# FM33A0XXER register map
File version: 1.0
CPU: SC000, little endian, no MPU, no FPU, 3 interrupt priority bits
Registers are 32-bit, read-write, reset 0x0 unless marked. A register's access mark holds for its fields unless they carry their own. Offsets are from the block's base; [hi:lo] are bit positions; {n}, {i} and the like mark numbered series.

## RTCVT — RTCVT module information
Base 0x40011000
0x2C VTMSEL — RTCVT Time Mark Select
  [3:0] FSEL — FSEL field description
0x30 VADJUST — RTCVT time Adjust Register
  [12:0] ADJUST — ADJUST field description
0x34 VADSIGN — RTCVT time Adjust Sign Register
  [0] ADSIGN — ADSIGN field description
0x38 VCAL — RTCVT Virtual Calibration Register
  [0] PR1SEN — PR1SEN field description

## LCD — LCD module information
Base 0x40010C00
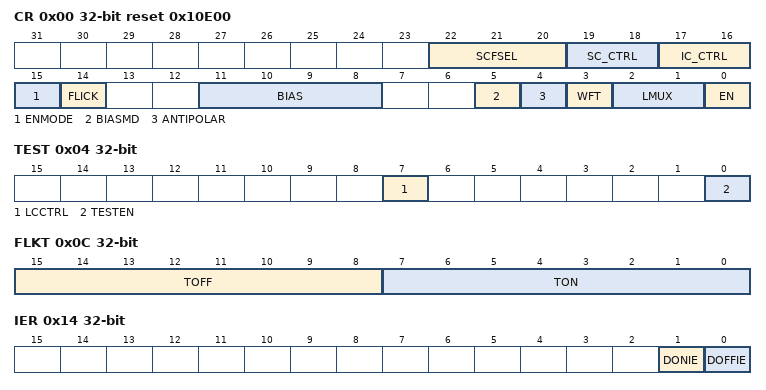
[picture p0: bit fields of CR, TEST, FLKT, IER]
0x00 CR reset 0x10E00 — LCD Control Register
  [22:20] SCFSEL — SCFSEL field description
  [19:18] SC_CTRL — SC_CTRL field description
  [17:16] IC_CTRL — IC_CTRL field description
  [15] ENMODE — ENMODE field description
  [14] FLICK — FLICK field description
  [11:8] BIAS — BIAS field description
  [5] BIASMD — BIASMD field description
  [4] ANTIPOLAR — ANTIPOLAR field description
  [3] WFT — WFT field description
  [2:1] LMUX — LMUX field description
  [0] EN — EN field description
0x04 TEST — LCD test Register
  [7] LCCTRL — LCCTRL field description
  [0] TESTEN — TESTEN field description
0x08 FCR — LCD Frequency Control Register
  [7:0] DF — DF field description
0x0C FLKT — LCD Flick Time Register
  [15:8] TOFF — TOFF field description
  [7:0] TON — TON field description
0x14 IER — LCD Interrupt Enable Register
  [1] DONIE — DONIE field description
  [0] DOFFIE — DOFFIE field description
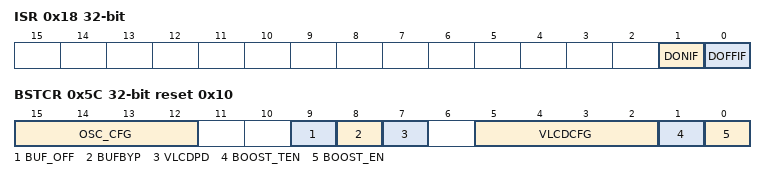
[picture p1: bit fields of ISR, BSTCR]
0x18 ISR — LCD Interrupt Status Register
  [1] DONIF — DONIF field description
  [0] DOFFIF — DOFFIF field description
{0x24+4i} DATA{i} (i=0..7) — LCD data buffer registers {i}
  [31:0] DSDA — DSDA field description
0x50 COMEN — LCD COM Enable Register
  [3:0] COMEN — COMEN field description
0x54 SEGEN0 — LCD SEG Enable Register0
  [31:0] SEGENx — SEGENx field description
0x58 SEGEN1 — LCD SEG Enable Register1
  [11:0] SEGENx — SEGENx field description
0x5C BSTCR reset 0x10 — LCD Boost Control Register
  [15:12] OSC_CFG — OSC_CFG field description
  [9] BUF_OFF — BUF_OFF field description
  [8] BUFBYP — BUFBYP field description
  [7] VLCDPD — VLCDPD field description
  [5:2] VLCDCFG — VLCDCFG field description
  [1] BOOST_TEN — BOOST_TEN field description
  [0] BOOST_EN — BOOST_EN field description

## ADC — ADC module information
Base 0x4001FA00
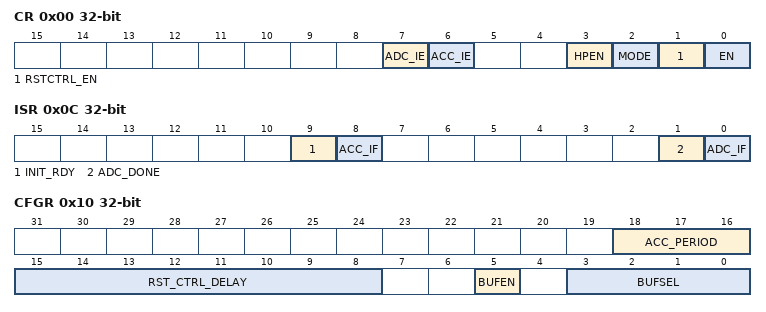
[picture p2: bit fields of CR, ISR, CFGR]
0x00 CR — ADC Control Register
  [7] ADC_IE — ADC_IE field description
  [6] ACC_IE — ACC_IE field description
  [3] HPEN — HPEN field description
  [2] MODE — MODE field description
  [1] RSTCTRL_EN — RSTCTRL_EN field description
  [0] EN — EN field description
0x04 TRIM — ADC Trim Register
  [10:0] ADC_TRIM — ADC_TRIM field description
0x08 DR — ADC Data Register
  [15:0] ADC_DATA ro — ADC_DATA field description
0x0C ISR — ADC Interrupt Status Regsiter
  [9] INIT_RDY ro — INIT_RDY field description
  [8] ACC_IF — ACC_IF field description
  [1] ADC_DONE ro — ADC_DONE field description
  [0] ADC_IF — ADC_IF field description
0x10 CFGR — ADC Config Register
  [18:16] ACC_PERIOD — ACC_PERIOD field description
  [15:8] RST_CTRL_DELAY — RST_CTRL_DELAY field description
  [5] BUFEN — BUFEN field description
  [3:0] BUFSEL — BUFSEL field description

## CIC — CIC module information
Base 0x40015C00
0x00 DR — CIC Output Data Register
  [23:0] ADC_CIC_DATA ro — ADC_CIC_DATA field description
0x04 OS — CIC Output Offset Register
  [23:0] ADC_CIC_OS — ADC_CIC_OS field description
0x08 USDR — CIC Unsigned Data Register
  [23:0] ADC_CIC_USDR ro — ADC_CIC_USDR field description
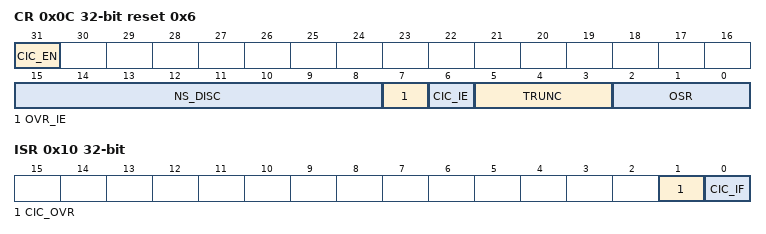
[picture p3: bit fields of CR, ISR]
0x0C CR reset 0x6 — CIC Control Register
  [31] CIC_EN — CIC_EN field description
  [15:8] NS_DISC — NS_DISC field description
  [7] OVR_IE — OVR_IE field description
  [6] CIC_IE — CIC_IE field description
  [5:3] TRUNC — TRUNC field description
  [2:0] OSR — OSR field description
0x10 ISR — CIC Interrupt Status Register
  [1] CIC_OVR — CIC_OVR field description
  [0] CIC_IF — CIC_IF field description
